# ATmega16HVA register map
Vendor: Atmel; File version: 1.0
CPU: other r0p0, little endian, no MPU, no FPU, 4 interrupt priority bits
Registers are 8-bit, read-write, reset 0x0 unless marked. A register's access mark holds for its fields unless they carry their own. Offsets are from the block's base; lines under a group give offsets from that group; [hi:lo] are bit positions; {n}, {i} and the like mark numbered series; 'fields as' and 'values as' point back to an identical list; <NAME> marks a mode.

## Memory map
0x00800000 FUSE size 0x1 — Fuses
0x00800000 LOCKBIT size 0x1 — Lockbits
0x00800020 PORTA size 0x3 — I/O Port
0x00800023 PORTB size 0x3 — I/O Port
0x00800026 PORTC blocks up to offset 0x3 — I/O Port
0x00800035 TC0 blocks up to offset 0x3A — Timer/Counter, 16-bit
0x00800036 TC1 blocks up to offset 0x54 — Timer/Counter, 16-bit
0x00800037 CPU blocks up to offset 0x48 — CPU Registers
0x0080003C EXINT blocks up to offset 0x2E — External Interrupts
0x0080003F EEPROM size 0x3
0x0080004C SPI size 0x3 — Serial Peripheral Interface
0x00800057 BOOT_LOAD size 0x1 — Bootloader
0x00800060 WDT size 0x1 — Watchdog Timer
0x00800078 ADC blocks up to offset 0x5 — Analog-to-Digital Converter
0x008000C8 VOLTAGE_REGULATOR size 0x1
0x008000D0 BANDGAP size 0x2
0x008000E0 COULOMB_COUNTER blocks up to offset 0xA
0x008000F0 FET size 0x1 — FET Control
0x008000F2 BATTERY_PROTECTION blocks up to offset 0xD

## Interrupts
0 RESET (CPU) — External Pin, Power-on Reset, Brown-out Reset and Watchdog Reset
1 BPINT (CPU) — Battery Protection Interrupt
2 VREGMON (CPU) — Voltage regulator monitor interrupt
3 INT0 (CPU) — External Interrupt Request 0
4 INT1 (CPU) — External Interrupt Request 1
5 INT2 (CPU) — External Interrupt Request 2
6 WDT (CPU) — Watchdog Timeout Interrupt
7 TIMER1_IC (CPU) — Timer 1 Input capture
8 TIMER1_COMPA (CPU) — Timer 1 Compare Match A
9 TIMER1_COMPB (CPU) — Timer 1 Compare Match B
10 TIMER1_OVF (CPU) — Timer 1 overflow
11 TIMER0_IC (CPU) — Timer 0 Input Capture
12 TIMER0_COMPA (CPU) — Timer 0 Compare Match A
13 TIMER0_COMPB (CPU) — Timer 0 Compare Match B
14 TIMER0_OVF (CPU) — Timer 0 Overflow
15 SPI_STC (CPU) — SPI Serial transfer complete
16 VADC (CPU) — Voltage ADC Conversion Complete
17 CCADC_CONV (CPU) — Coulomb Counter ADC Conversion Complete
18 CCADC_REG_CUR (CPU) — Coloumb Counter ADC Regular Current
19 CCADC_ACC (CPU) — Coloumb Counter ADC Accumulator
20 EE_READY (CPU) — EEPROM Ready

## ADC — Analog-to-Digital Converter
Base 0x00800078
0x00 VADC 16-bit (reset mask 0xFF) — VADC Data Register Bytes
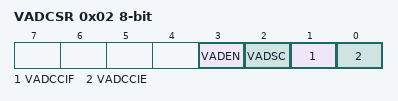
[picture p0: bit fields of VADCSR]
0x02 VADCSR — The VADC Control and Status register (read-only for debugger)
  [3] VADEN — VADC Enable
  [2] VADSC — VADC Satrt Conversion
  [1] VADCCIF — VADC Conversion Complete Interrupt Flag
  [0] VADCCIE — VADC Conversion Complete Interrupt Enable
0x04 VADMUX — The VADC multiplexer Selection Register
  [3:0] VADMUX — Analog Channel and Gain Selection Bits

## BANDGAP
Base 0x008000D0
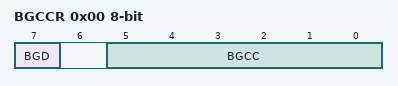
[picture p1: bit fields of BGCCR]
0x00 BGCCR — Bandgap Calibration Register
  [7] BGD — Setting the BGD bit to one will disable the bandgap voltage reference. This bit must be cleared before enabling CC-ADC or V-ADC, and must remain unset while either ADC is enabled.
  [5:0] BGCC — BG Calibration of PTAT Current Bits
0x01 BGCRR — Bandgap Calibration of Resistor Ladder
  [7:0] BGCR — Bandgap calibration bits

## BATTERY_PROTECTION
Base 0x008000F2
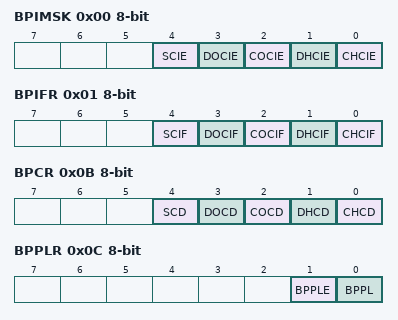
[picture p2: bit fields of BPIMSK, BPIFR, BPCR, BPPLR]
0x00 BPIMSK — Battery Protection Interrupt Mask Register
  [4] SCIE — Short-circuit Protection Activated Interrupt Enable
  [3] DOCIE — Discharge Over-current Protection Activated Interrupt Enable
  [2] COCIE — Charge Over-current Protection Activated Interrupt Enable
  [1] DHCIE — Discharger High-current Protection Activated Interrupt
  [0] CHCIE — Charger High-current Protection Activated Interrupt
0x01 BPIFR — Battery Protection Interrupt Flag Register
  [4] SCIF — Short-circuit Protection Activated Interrupt Flag
  [3] DOCIF — Discharge Over-current Protection Activated Interrupt Flag
  [2] COCIF — Charge Over-current Protection Activated Interrupt Flag
  [1] DHCIF — Discharge High-current Protection Activated Interrupt
  [0] CHCIF — Charge High-current Protection Activated Interrupt
0x03 BPSCD — Battery Protection Short-Circuit Detection Level Register
0x04 BPDOCD — Battery Protection Discharge-Over-current Detection Level Register
0x05 BPCOCD — Battery Protection Charge-Over-current Detection Level Register
0x06 BPDHCD — Battery Protection Discharge-High-current Detection Level Register
0x07 BPCHCD — Battery Protection Charge-High-current Detection Level Register
0x08 BPSCTR — Battery Protection Short-current Timing Register
0x09 BPOCTR — Battery Protection Over-current Timing Register
0x0A BPHCTR — Battery Protection Short-current Timing Register
0x0B BPCR — Battery Protection Control Register
  [4] SCD — Short Circuit Protection Disabled
  [3] DOCD — Discharge Over-current Protection Disabled
  [2] COCD — Charge Over-current Protection Disabled
  [1] DHCD — Discharge High-current Protection Disable
  [0] CHCD — Charge High-current Protection Disable
0x0C BPPLR — Battery Protection Parameter Lock Register (read-only for debugger)
  [1] BPPLE — Battery Protection Parameter Lock Enable
  [0] BPPL — Battery Protection Parameter Lock
